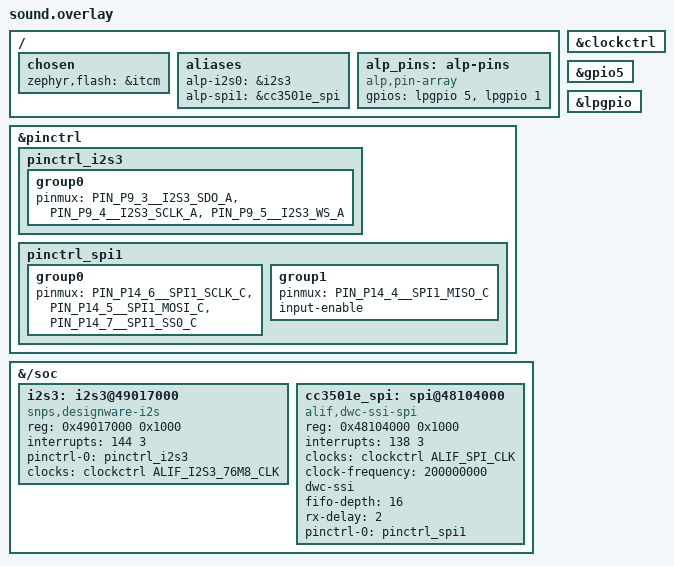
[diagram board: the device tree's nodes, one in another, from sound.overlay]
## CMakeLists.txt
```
# sound/ -- Trace Runner game sound: src/audio's synth on I2S3 -> both
# TAS2563 amps. docs/2026-09-23-sound.md has the build/bench recipes.
#
#   TR_SND_MODE=GAME  (default) the M55-HP firmware: drains the HE's event
#                     ring (src/ipc/tr_aring.h, SRAM0 0x0237F000) into the synth.
#   TR_SND_MODE=TEST  standalone sound test: music + a scripted SFX run, a
#                     1 kHz reference tone, and a PDM-mic loopback capture to
#                     SRAM0 0x02000000 with an in-band PASS/FAIL.
cmake_minimum_required(VERSION 3.20)

set(TR_SND_MODE GAME CACHE STRING "GAME (HP, reads the HE ring) or TEST (standalone loopback test)")
set_property(CACHE TR_SND_MODE PROPERTY STRINGS GAME TEST)
if(NOT TR_SND_MODE MATCHES "^(GAME|TEST)$")
	message(FATAL_ERROR "TR_SND_MODE must be GAME or TEST, got '${TR_SND_MODE}'")
endif()

# Enabling i2s3 drives P9_3/4/5. On an EVK 2626-R2 carrier whose U46 is the
# stock 74LVC157 that contends with U46's outputs (no Hi-Z) the moment the
# pins are muxed -- only a carrier reworked to a 3257-type bus switch (VCC on
# +3V3, E1M-AEN803 serial 2026W36-0002's carrier) may run this image.
option(TR_SND_REWORKED_U46 "Carrier's U46 I2S mux is a reworked 3257-type switch on +3V3" OFF)
if(NOT TR_SND_REWORKED_U46)
	message(FATAL_ERROR "sound/ drives I2S3 through U46: build only for a carrier with the "
		"reworked U46 (-DTR_SND_REWORKED_U46=ON). Stock 74LVC157 carriers contend on P9_3/4/5.")
endif()

list(APPEND DTC_OVERLAY_FILE ${CMAKE_CURRENT_LIST_DIR}/sound.overlay)
# TEST only: OFF = play-only (no PDM node, no DMIC driver, no capture) -- the
# quickest bench check that I2S3 streams, and a split if PDM + I2S3 together
# ever misbehave.
option(TR_SND_MIC "TEST image also captures the PDM mics (loopback verdict)" ON)
if(TR_SND_MODE STREQUAL "TEST")
	if(TR_SND_MIC)
		list(APPEND DTC_OVERLAY_FILE ${CMAKE_CURRENT_LIST_DIR}/pdm.overlay)
		list(APPEND EXTRA_CONF_FILE ${CMAKE_CURRENT_LIST_DIR}/mic.conf)
	endif()
	list(APPEND EXTRA_CONF_FILE ${CMAKE_CURRENT_LIST_DIR}/test.conf)
endif()

find_package(Zephyr REQUIRED HINTS $ENV{ZEPHYR_BASE})
project(trace_runner_sound LANGUAGES C)

# I2S3 and the PDM run off the CGU's 76.8 MHz audio source, which only
# alp-sdk's clockctrl patch (zephyr/patches/zephyr/0001-clock_control_alif-
# master-source-expmst-i2s-setrate.patch) turns on. Unpatched, i2s_dw
# tolerates the missing set_rate silently: the build is clean, the first
# write queues, and nothing ever clocks out (bench, 2026-09-23). Refuse.
file(READ ${ZEPHYR_BASE}/drivers/clock_control/clock_control_alif.c _tr_clkctl)
string(FIND "${_tr_clkctl}" "ALIF_EXPMST0_CTRL_REG_OFF" _tr_patched)
if(_tr_patched EQUAL -1)
	message(FATAL_ERROR "${ZEPHYR_BASE}/drivers/clock_control/clock_control_alif.c lacks alp-sdk's "
		"clockctrl patch (no 76.8 MHz audio clock for I2S3/PDM). Build against a patched tree, "
		"e.g. ZEPHYR_BASE=$ZEPHYR_BASE (docs/2026-09-23-sound.md).")
endif()

target_sources(app PRIVATE
	src/main.c
	src/cc3501e_bridge.c
	src/cc3501e_gpio_routes.c
	../src/audio/tr_audio.c
	../src/audio/tr_amp_ready.c
	../src/ipc/tr_aring.c
)
target_include_directories(app PRIVATE ../src)
# Synth build (bench A/B): TR_SND_V2=OFF renders the first synth version;
# TR_SND_RATE=48000 needs V2 (16 kHz and 48 kHz divide 76.8 MHz exactly).
option(TR_SND_V2 "Band-limited synth + soft limiter + level trims (TR_AUDIO_V2)" ON)
option(TR_SND_V3 "Small-speaker voicing: 4th-order 450 Hz master high-pass + everything voiced from ~500 Hz (TR_AUDIO_V3, needs V2)" ON)
set(TR_SND_RATE 16000 CACHE STRING "Synth and I2S3 rate: 16000 or 48000")
set(TR_SND_VOLUME "" CACHE STRING "Digital volume 0..255 (empty = 255, unity)")
set(TR_SND_AMP_LEVEL "" CACHE STRING "TAS2563 amp analog level code, int or hex 0x01..0x10 (empty = 0x10, 16.0 dBV)")
# Extra TAS2563 register writes for bench A/B, e.g. amp_regs_dvc_minus6db.h
# (DVC -6 dB). Default NONE = the amps' POR DVC 0 dB: round 3 showed no amp
# fault latch in any window with or without it, and it cost 6 dB at the mic.
set(TR_SND_AMP_REGS_FILE NONE CACHE STRING
	"Header defining TR_SND_AMP_REGS (extra TAS2563 writes), or NONE")
target_compile_definitions(app PRIVATE TR_AUDIO_V2=$<BOOL:${TR_SND_V2}> TR_AUDIO_RATE=${TR_SND_RATE}u
	TR_AUDIO_V3=$<AND:$<BOOL:${TR_SND_V2}>,$<BOOL:${TR_SND_V3}>>)
if(TR_SND_VOLUME)
	target_compile_definitions(app PRIVATE TR_SND_VOLUME=${TR_SND_VOLUME}u)
endif()
if(TR_SND_AMP_LEVEL)
	target_compile_definitions(app PRIVATE TR_SND_AMP_LEVEL=${TR_SND_AMP_LEVEL}u)
endif()
if(TR_SND_AMP_REGS_FILE AND NOT TR_SND_AMP_REGS_FILE STREQUAL "NONE")
	target_compile_definitions(app PRIVATE TR_SND_AMP_REGS_FILE="${TR_SND_AMP_REGS_FILE}")
endif()
target_compile_definitions(app PRIVATE TR_SND_TEST=$<IF:$<STREQUAL:${TR_SND_MODE},TEST>,1,0>
	TR_SND_MIC=$<IF:$<AND:$<STREQUAL:${TR_SND_MODE},TEST>,$<BOOL:${TR_SND_MIC}>>,1,0>)
# Same bits as the host tests (the synth is integer-only, but keep the rule).
target_compile_options(app PRIVATE -ffp-contract=off)
```

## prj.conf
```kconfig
# Trace Runner sound firmware (sound/): I2S3 -> both TAS2563 amps, fed by
# src/audio/tr_audio.c. Kconfig set taken from the bench-proven
# aen-i2s-tas2563-probe (2026W36-0002, 2026-09-15) and alp-sdk aen-evk-demo.
CONFIG_ALP_SDK=y

# CC3501E bridge: the I2S0 mux /E + S are CC3501E GPIOs (E1M IO8/IO13).
CONFIG_SPI=y
CONFIG_GPIO=y
CONFIG_ALP_SDK_CHIP_CC3501E=y
CONFIG_ALP_SDK_GPIO_CC3501E_PROXY=y
# IO8 is revision-dependent: the proxy opens it only once the identity
# EEPROM (carrier bus 0 @ 0x50) confirms this hw_rev.
CONFIG_ALP_SDK_CHIP_EEPROM_24C128=y
CONFIG_ALP_SDK_HW_INFO_EEPROM_I2C_BUS_ID=0
CONFIG_ALP_SDK_HW_INFO_EEPROM_I2C_BITRATE_HZ=100000
CONFIG_ALP_SDK_SOM_HW_REV="2626-r2"

# I2S3 TX (<alp/audio.h> audio_out) + TAS2563 x2 over I2C.
CONFIG_I2S=y
CONFIG_AUDIO=y
CONFIG_ALP_SDK_CHIP_TAS2563=y
CONFIG_I2C=y
CONFIG_PINCTRL=y
CONFIG_HEAP_MEM_POOL_SIZE=16384
CONFIG_MAIN_STACK_SIZE=8192

# D-cache maintenance hangs on this silicon, and the event ring in SRAM0 is
# shared with the other M55 -- off (as every AEN bench app and the game).
CONFIG_DCACHE=n
CONFIG_FPU=y
CONFIG_SPEED_OPTIMIZATIONS=y

# RAM console only ('ram_console_buf' over SWD); the HE game owns the UART.
CONFIG_CONSOLE=y
CONFIG_RAM_CONSOLE=y
CONFIG_RAM_CONSOLE_BUFFER_SIZE=8192
CONFIG_UART_CONSOLE=n
CONFIG_PRINTK=y
CONFIG_LOG=n
```

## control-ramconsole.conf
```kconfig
# Extra conf for the 2026W36-0002 CONTROL images (alp-sdk aen-i2s-amp-alif and the
# aen-i2s-tas2563-probe): route printk to 'ram_console_buf', which the Flow C
# helper in alp-sdk scripts/bench/aen reads back (it requires the symbol).
CONFIG_RAM_CONSOLE=y
CONFIG_RAM_CONSOLE_BUFFER_SIZE=16384
CONFIG_UART_CONSOLE=n
```

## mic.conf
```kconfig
# TR_SND_MIC=ON: the PDM mic driver for the loopback capture (pdm.overlay).
CONFIG_AUDIO_DMIC=y
```

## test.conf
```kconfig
# TR_SND_MODE=TEST: float printf for the analysis lines. The DMIC driver
# comes from mic.conf (TR_SND_MIC=ON only).
CONFIG_CBPRINTF_FP_SUPPORT=y
```

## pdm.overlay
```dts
/*
 * Copyright (c) 2026 Alp Lab AB
 * SPDX-License-Identifier: Apache-2.0
 *
 * PDM mics U19/U20 (TR_SND_MODE=TEST only: the loopback listener). From the
 * bench-proven aen-i2s-tas2563-probe overlay: C0 = P6_1, D0 = P6_0, 48 kHz
 * (the MP34DT05 needs a 1.2-3.25 MHz PDM clock; 8/16 kHz modes are below it).
 */
&pinctrl {
	pinctrl_pdm0: pinctrl_pdm0 {
		group0 {
			pinmux = <PIN_P6_1__PDM_C0_C>;
		};
		group1 {
			pinmux = <PIN_P6_0__PDM_D0_C>;
			input-enable;
		};
	};
};

&{/soc} {
	pdm: pdm@4902d000 {
		compatible = "alif,alif-pdm";
		reg = <0x4902d000 0x1000>;
		interrupts = <145 3>, <146 3>, <147 3>;
		interrupt-names = "warning_intr", "error_intr", "audio_det_intr";
		pinctrl-0 = <&pinctrl_pdm0>;
		pinctrl-names = "default";
		clocks = <&clockctrl ALIF_PDM_76M8_CLK>;
		fifo_watermark = <5>;
		bypass_iir_filter = <1>;
		clk-frequency-min = <1200000>;
		clk-frequency-max = <3250000>;
		status = "okay";
	};
};

/ {
	aliases {
		alp-pdm0 = &pdm;
	};
};
```

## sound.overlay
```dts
/*
 * Copyright (c) 2026 Alp Lab AB
 * SPDX-License-Identifier: Apache-2.0
 *
 * Trace Runner sound (sound/): shared by the M55-HE and M55-HP targets --
 * the two AEN803 board files differ only in TCM bases (see
 * docs/2026-09-23-sound.md). Transcribed from the bench-proven
 * aen-i2s-tas2563-probe overlay (2026W36-0002 audible playback 2026-09-15) and
 * alp-sdk examples/aen/aen-evk-demo (AEN803): i2s3 on P9_3/4/5, gpio5 for
 * the amps' SD_N (P5_2) / IRQZ (P5_0), and the CC3501E bridge (SPI1 + the
 * LP-GPIO WIFI_EN/nRESET) that drives the I2S0 mux.
 *
 * i2s3 is ENABLED here. On a carrier whose U46 is the stock 74LVC157 that
 * alone contends with U46's outputs on P9_3/4/5 (alp-sdk
 * examples/aen/aen-i2s-amp-alif README, SAFETY). CMakeLists.txt refuses to
 * build without -DTR_SND_REWORKED_U46=ON for that reason.
 */
#include <zephyr/dt-bindings/pinctrl/alif-ensemble-pinctrl.h>
#include <zephyr/dt-bindings/clock/alif-ensemble-clocks-ext.h>
#include <zephyr/dt-bindings/gpio/gpio.h>

/ {
	chosen {
		zephyr,flash = &itcm; /* RAM-run / SE-load into this core's ITCM */
		/delete-property/ zephyr,code-partition;
	};
	aliases {
		alp-i2s0 = &i2s3;
		alp-spi1 = &cc3501e_spi; /* bus_id 1 in alp_spi_open() */
	};
	/* SoM-internal CC3501E control nets, in cc3501e_bridge.h's
	 * CC3501E_BRIDGE_PIN_* order. Exactly ONE alp,pin-array in the tree. */
	alp_pins: alp-pins {
		compatible = "alp,pin-array";
		gpios = <&lpgpio 5 GPIO_ACTIVE_HIGH>, /* [0] WIFI_EN     (P15_5)      */
			<&lpgpio 1 GPIO_ACTIVE_HIGH>; /* [1] E_WIFI.NRST (P15_1_FLEX) */
	};
};

&pinctrl {
	pinctrl_i2s3: pinctrl_i2s3 {
		group0 {
			pinmux = <PIN_P9_3__I2S3_SDO_A>, <PIN_P9_4__I2S3_SCLK_A>,
				 <PIN_P9_5__I2S3_WS_A>;
		};
	};
	/* SPI1 on P14_6 SCK / P14_5 MOSI / P14_4 MISO + hardware SS0 on P14_7
	 * (the dwc-ssi's own select frames each bridge phase -- no cs-gpios). */
	pinctrl_spi1: pinctrl_spi1 {
		group0 {
			pinmux = <PIN_P14_6__SPI1_SCLK_C>, <PIN_P14_5__SPI1_MOSI_C>,
				 <PIN_P14_7__SPI1_SS0_C>;
		};
		group1 {
			pinmux = <PIN_P14_4__SPI1_MISO_C>;
			input-enable;
		};
	};
};

&{/soc} {
	i2s3: i2s3@49017000 {
		compatible = "snps,designware-i2s";
		reg = <0x49017000 0x1000>;
		interrupts = <144 3>;
		pinctrl-0 = <&pinctrl_i2s3>;
		pinctrl-names = "default";
		clocks = <&clockctrl ALIF_I2S3_76M8_CLK>;
		status = "okay";
	};
	cc3501e_spi: spi@48104000 {
		compatible = "alif,dwc-ssi-spi";
		#address-cells = <1>;
		#size-cells = <0>;
		reg = <0x48104000 0x1000>;
		interrupts = <138 3>;
		clocks = <&clockctrl ALIF_SPI_CLK>;
		clock-frequency = <200000000>;
		dwc-ssi;
		fifo-depth = <16>;
		rx-delay = <2>;
		pinctrl-0 = <&pinctrl_spi1>;
		pinctrl-names = "default";
		status = "okay";
	};
};

&clockctrl {
	status = "okay";
};

&gpio5 {
	status = "okay";
};

&lpgpio {
	status = "okay";
};
```

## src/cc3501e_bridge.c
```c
/*
 * SPDX-License-Identifier: Apache-2.0
 * Copyright 2026 Alp Lab AB
 *
 * E1M-AEN SoM CC3501E bridge bring-up helper -- see cc3501e_bridge.h.
 * Copied from alp-sdk examples/aen/aen-evk-demo/src/cc3501e_bridge.c; the
 * one change: the LP-pad output enable below also runs on the M55-HP
 * (sound/ runs there in the game), not only on the HE.  The warm-aware final
 * reset (no WIFI_EN cycle on a running CC3501E, issue #2797) matches the
 * canonical copy.
 */

#include "cc3501e_bridge.h"

#include <stdio.h>

#if defined(TR_SND_EMBED) && TR_SND_EMBED
/* Combined HP image (sound/src/main.c): the proxy attach below reads the identity EEPROM @0x50
 * on I2C2, which the HE may own -- lease the bus for it (Dekker entry, src/ipc/tr_bus2.h) and
 * GIVE IT BACK right after, before the long, bus-free CC3501E reset: this core's I2C2 IRQ is off
 * and the HE owns the bus again for that whole stretch. A take-back seen at the entry aborts the
 * bring-up (main.c reads its s_aborted); a retry reuses the control-pin and SPI handles opened
 * here. */
#include <stdbool.h>
bool tr_snd_bus_enter(void);
void tr_snd_bus_release(void);
#define BRIDGE_EMBED 1
static alp_gpio_t *s_wifi_en, *s_nrst;
static alp_spi_t  *s_spi;
#else
#define BRIDGE_EMBED 0
#endif

#if defined(CONFIG_SOC_AE822FA0E5597LS0_RTSS_HE) || defined(CONFIG_SOC_AE822FA0E5597LS0_RTSS_HP)
#include <zephyr/arch/cpu.h>
#include <zephyr/devicetree.h>
#include <zephyr/sys/sys_io.h>
/*
 * AEN LP-pad mux (Alif Ensemble E8, M55-HE).  WIFI_EN (P15_5) and nRESET (P15_1)
 * are on the Alif LP-GPIO island, bound by the generic snps,designware-gpio driver
 * which does NOT apply Alif pinctrl -- so the LP pads stay un-muxed and their output
 * drivers OFF (confirmed on silicon: WIFI_EN never powers the CC3501E until these
 * regs are set).  0x23 = the Alif GPIO-output pad config (driver + read-enable +
 * drive strength).  TODO: drop this raw poke once the Alif GPIO backend muxes the LP
 * island via pinctrl.
 */
#define ALIF_LPGPIO_PADCTRL_BASE 0x42007000u
#define ALIF_PAD_GPIO_OUTPUT     0x23u
static void aen_lp_pads_enable_output(void)
{
	sys_write32(ALIF_PAD_GPIO_OUTPUT, ALIF_LPGPIO_PADCTRL_BASE + 5u * 4u); /* P15_5 WIFI_EN */
	sys_write32(ALIF_PAD_GPIO_OUTPUT, ALIF_LPGPIO_PADCTRL_BASE + 1u * 4u); /* P15_1 nRESET  */
}

/* Latch an LP-GPIO pin HIGH in the port's data register while the pad is still an
 * INPUT.  Switching the direction afterwards then drives the already-high level; the
 * other order (direction first, value second -- what gpio_dw's configure does even
 * with an init flag) drives whatever DR holds, and after an LP-GPIO reset that is 0:
 * a glitch on WIFI_EN (P15_5, bit 5) drops the supply of a running chip, one on
 * nRESET (P15_1, bit 1) asserts its reset.  DR is written directly (read-modify-write, the
 * same access gpio_dw's port_set_bits_raw makes) so this template stays on the
 * portable <alp/...> headers: SWPORTA_DR is offset 0x00 of the DesignWare GPIO block
 * (zephyr drivers/gpio/gpio_dw_registers.h), the block base is the `lpgpio` node's
 * reg, and the LP-GPIO clock is already on because alp_gpio_open() opened the pin. */
#define DW_GPIO_SWPORTA_DR 0x00u
static void aen_lp_gpio_latch_high(unsigned int bit)
{
	const mem_addr_t dr = DT_REG_ADDR(DT_NODELABEL(lpgpio)) + DW_GPIO_SWPORTA_DR;

	sys_write32(sys_read32(dr) | (1u << bit), dr);
}

#else
static inline void aen_lp_pads_enable_output(void)
{
}

static inline void aen_lp_gpio_latch_high(unsigned int bit)
{
	(void)bit;
}
#endif

alp_status_t cc3501e_bridge_bringup(cc3501e_t *fw)
{
	if (fw == NULL) {
		return ALP_ERR_INVAL;
	}

	/* 1. Control pins: WIFI_EN (supply gate) + nRESET.  These are Alif LP-GPIO
	 *    pads, not E1M edge pads -- the SoM owns them. */
#if BRIDGE_EMBED
	alp_gpio_t *wifi_en = s_wifi_en != NULL ? s_wifi_en : alp_gpio_open(CC3501E_BRIDGE_PIN_WIFI_EN);
	alp_gpio_t *nrst    = s_nrst != NULL ? s_nrst : alp_gpio_open(CC3501E_BRIDGE_PIN_NRST);
	s_wifi_en           = wifi_en;
	s_nrst              = nrst;
#else
	alp_gpio_t *wifi_en = alp_gpio_open(CC3501E_BRIDGE_PIN_WIFI_EN);
	alp_gpio_t *nrst    = alp_gpio_open(CC3501E_BRIDGE_PIN_NRST);
#endif
	if (wifi_en == NULL || nrst == NULL) {
		if (wifi_en != NULL) {
			alp_gpio_close(wifi_en);
		}
		if (nrst != NULL) {
			alp_gpio_close(nrst);
		}
		return ALP_ERR_NOT_PRESENT_ON_THIS_SOC;
	}
	aen_lp_pads_enable_output();
	/* Sample the supply gate BEFORE touching its direction.  High is only a HINT
	 * that the chip may be powered -- an external pull-up on WIFI_EN would make every
	 * power-on read high (whether the module has one is an OPEN QUESTION; the
	 * netlist has not been checked), so the decision below also needs a PING. */
	bool wifi_was_high = false;
	/* A failed read leaves the level unknown: never take the supply-cycling cold path
	 * on that alone -- go through the PING path below, which still ends in
	 * cc3501e_reset() if the chip turns out to be silent. */
	const bool wifi_unknown = alp_gpio_read(wifi_en, &wifi_was_high) != ALP_OK;
	if (wifi_was_high || wifi_unknown) {
		/* Latch the level in DR first so the direction change cannot glitch it low.  An
		 * unknown level is latched high too: DR bit 5 = 0 would otherwise drop the supply
		 * of a chip that is already running the moment the pin becomes an output. */
		aen_lp_gpio_latch_high(5u); /* P15_5 WIFI_EN */
	}
	/* Same for nRESET: a running chip has it released (high).  Without the latch the
	 * direction change below drives DR bit 1 = 0 and holds the chip in reset, so the
	 * warm PING always fails and the bring-up falls through to a WIFI_EN supply cycle. */
	bool nrst_was_high = false;
	if (alp_gpio_read(nrst, &nrst_was_high) == ALP_OK && nrst_was_high) {
		aen_lp_gpio_latch_high(1u); /* P15_1 nRESET */
	}
	(void)alp_gpio_configure(wifi_en, ALP_GPIO_OUTPUT, ALP_GPIO_PULL_NONE);
	(void)alp_gpio_configure(nrst, ALP_GPIO_OUTPUT, ALP_GPIO_PULL_NONE);

	/* 2. Inter-chip SPI (Alif = master).  CS is the dwc-ssi hardware SS0
	 *    muxed on P14_7; the app passes ALP_SPI_NO_CS so no software GPIO CS
	 *    is installed and the SPI controller drives SS0 per transfer.  Mode 0
	 *    matches the CC3501E vendor image frameFormat. */
#if BRIDGE_EMBED
	alp_spi_t *spi = s_spi != NULL ? s_spi : alp_spi_open(&(alp_spi_config_t) {
#else
	alp_spi_t *spi = alp_spi_open(&(alp_spi_config_t){
#endif
		.bus_id = CC3501E_BRIDGE_SPI_BUS_ID, .freq_hz = CC3501E_BRIDGE_SPI_FREQ_HZ,
		.mode = ALP_SPI_MODE_0, .bits_per_word = 8u, .cs_pin_id = ALP_SPI_NO_CS,
	});
#if BRIDGE_EMBED
	s_spi = spi;
#endif
	if (spi == NULL) {
		alp_gpio_close(wifi_en);
		alp_gpio_close(nrst);
		return ALP_ERR_NOT_PRESENT_ON_THIS_SOC;
	}

#if CC3501E_BRIDGE_RX_SAMPLE_DLY > 0
	/* Raise the SCLK past 1 MHz: the DW SSI RX_SAMPLE_DLY register (0xf0) delays
	 * the MISO capture point by N ssi_clk cycles to cover the on-SoM trace + crossed
	 * data round-trip.  Zephyr spi_dw never writes it (leaves 0), so without this
	 * >1 MHz mis-samples MISO (cold reqhdr_rx=0xFFFFFFFF).  Written with SSI disabled
	 * (SSIENR=0); persists across the driver's per-transfer configure.  Value is
	 * silicon-tuned -- sweep CC3501E_BRIDGE_RX_SAMPLE_DLY at the target SCLK.
	 *
	 * SWEEP TRAP -- read before setting the constant to 0: the `#if > 0` above
	 * compiles this block out, so 0 does not mean "no delay", it means the SPI
	 * node's `rx-delay` devicetree value is left in place.  aen-cc3501e-bringup
	 * and aen-evk-demo declare rx-delay = <2>, so a naive N=0 sweep point on
	 * those two silently measures 2.  Read 0x481040F0 back to see what the link
	 * is actually running at. */
	{
		volatile uint32_t *ssienr =
		    (volatile uint32_t *)(uintptr_t)(CC3501E_BRIDGE_SPI1_BASE + 0x08u);
		volatile uint32_t *rsd = (volatile uint32_t *)(uintptr_t)(CC3501E_BRIDGE_SPI1_BASE + 0xf0u);
		uint32_t           en  = *ssienr;
		*ssienr                = 0u;
		*rsd                   = (uint32_t)CC3501E_BRIDGE_RX_SAMPLE_DLY;
		*ssienr                = en;
	}
#endif

	/* 3. Bind the bus + control pins; attach the GPIO proxy (proxied E1M IOs then
	 *    route over the bridge); run the power + reset sequence (TI SWRU626 + the
	 *    Puya cold-boot hard-reset workaround).  Leaves WIFI_EN HIGH. */
	(void)cc3501e_init(fw, spi);
	fw->enable_pin = wifi_en;
	fw->reset_pin  = nrst;
	/* READY (CC35 GPIO17) is NOT wired here by default on this R2 module --
	 * see chips/cc3501e/cc3501e_core.c's cc3501e_reply_gate() comment for the
	 * pin-routing fact, the bench evidence, and how a board that genuinely
	 * wires it can opt back in via fw->ready_pin. */
#ifdef CONFIG_ALP_SDK_GPIO_CC3501E_PROXY
#if BRIDGE_EMBED
	if (!tr_snd_bus_enter()) {
		return ALP_ERR_BUSY; /* the HE took I2C2 back: no EEPROM read */
	}
#endif
	(void)alp_gpio_cc3501e_attach(fw); /* reads the identity EEPROM @0x50 on I2C2 */
#if BRIDGE_EMBED
	tr_snd_bus_release();
#endif
#endif
#ifdef CONFIG_ALP_SDK_WIFI_CC3501E
	(void)alp_wifi_cc3501e_attach(fw);
#endif
#ifdef CONFIG_ALP_SDK_BLE_CC3501E
	(void)alp_ble_cc3501e_attach(fw);
#endif
	/* One line naming the path taken, so a log shows whether the supply was cycled. */
	if (!wifi_was_high && !wifi_unknown) {
		printf("[cc3501e_bridge] WIFI_EN low: cold power-up (cc3501e_reset)\n");
		return cc3501e_reset(fw); /* supply low: the full cold-boot sequence */
	}
	/* WIFI_EN reads high.  Warm = the chip ANSWERS a PING; a pull-up alone proves
	 * nothing.  Warm: nRESET only, never a WIFI_EN toggle. */
	if (cc3501e_ping(fw) == ALP_OK) {
		printf("[cc3501e_bridge] WIFI_EN high, PING ok: warm, nRESET only\n");
		return cc3501e_hard_reset(fw);
	}
	/* High but silent: powered-and-hung, or unpowered behind a pull-up.  Try the
	 * nRESET-only reset first (safe for a powered chip); only if the chip still does
	 * not answer is the supply cycled -- the last resort, taken from a chip that is
	 * already unresponsive. */
	if (cc3501e_hard_reset(fw) == ALP_OK && cc3501e_ping(fw) == ALP_OK) {
		printf("[cc3501e_bridge] WIFI_EN high, silent: recovered by nRESET only\n");
		return ALP_OK;
	}
	printf("[cc3501e_bridge] WIFI_EN high, silent after nRESET: supply cycle (cc3501e_reset)\n");
	return cc3501e_reset(fw);
}
```

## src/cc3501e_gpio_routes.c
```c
/*
 * SPDX-License-Identifier: Apache-2.0
 * Copyright 2026 Alp Lab AB
 *
 * Strong override of the SDK's WEAK (empty) cc3501e_gpio_routes[]: the two
 * CC3501E-proxied pins this app drives, the I2S0 mux in front of the TAS2563
 * amps. Same table as the bench-proven aen-i2s-tas2563-probe; hw_rev
 * 2626-r2 routes (IO8 -> GPIO_30 holds only on r2 -- the SDK's per-pin guard
 * refuses IO8 unless the identity EEPROM confirms CONFIG_ALP_SDK_SOM_HW_REV).
 */
#include <stddef.h>

#include <alp/chips/cc3501e.h>
#include <alp/e1m_pinout.h>

const cc3501e_gpio_route_t cc3501e_gpio_routes[] = {
	{ ALP_E1M_GPIO_IO13,
	  13u }, /* I2S0 mux S (I2S_SELECT): 0 = TAS2563 amps. NEVER drive 1 on a reworked carrier. */
	{ ALP_E1M_GPIO_IO8, 30u }, /* I2S0 mux /E (I2S_EN), active low. */
};
const size_t cc3501e_gpio_route_count =
    sizeof(cc3501e_gpio_routes) / sizeof(cc3501e_gpio_routes[0]);
```

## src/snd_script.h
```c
/* sound/src/snd_script.h -- the TEST image's per-effect loopback script,
 * shared with tools/audio_preview.c (--script) so the PC renders the exact
 * samples the image streams: same windows, same seeds, same synth build.
 *
 * Every window restarts the synth (tr_audio_init) so each clip is isolated
 * and deterministic; the stream itself never stops. Window lengths are in
 * 16 ms blocks (SND_BLOCK_MS), the I2S and mic block period at any rate.
 */
#ifndef SND_SCRIPT_H
#define SND_SCRIPT_H

#include <stdint.h>
#include <string.h>

#include "audio/tr_audio.h"
#include "ipc/tr_mbox.h" /* TR_CRASH_KIND_* */

#define SND_BLOCK_MS 16u
#define SND_FRAMES   (TR_AUDIO_RATE * SND_BLOCK_MS / 1000u) /* 256 at 16 kHz, 768 at 48 kHz */
#define SND_SEED     0x7E57u

enum { SND_W_SILENCE, SND_W_TONE, SND_W_MUSIC, SND_W_SFX };

typedef struct {
	uint8_t     type, kind, param;
	uint16_t    hz, amp; /* SND_W_TONE: frequency, peak amplitude (S16) */
	uint16_t    blocks;
	const char *name;
} snd_win_t;

/* 1 kHz at -12 and -3 dBFS, and 200/300/500 Hz at -6 dBFS: harmonic
 * distortion of the chain vs level, and where the speakers' usable low end
 * starts (200 Hz came back THD +33.9 dB on 2026-09-23). Music from bar 9 (lead + drums). Each effect alone. */
static const snd_win_t snd_windows[] = {
	{ SND_W_SILENCE, 0, 0, 0, 0, 31, "silence" },
	{ SND_W_TONE, 0, 0, 1000, 8231, 62, "tone1k_-12dBFS" },
	{ SND_W_TONE, 0, 0, 1000, 23197, 62, "tone1k_-3dBFS" },
	{ SND_W_TONE, 0, 0, 200, 16423, 62, "tone200_-6dBFS" },
	{ SND_W_TONE, 0, 0, 300, 16423, 62, "tone300_-6dBFS" },
	{ SND_W_TONE, 0, 0, 400, 16423, 62, "tone400_-6dBFS" },
	{ SND_W_TONE, 0, 0, 500, 16423, 62, "tone500_-6dBFS" },
	{ SND_W_MUSIC, TR_AEV_MUSIC, TR_MUSIC_PLAY, 0, 0, 625, "music" },
	{ SND_W_SFX, TR_AEV_FOOTSTEP, 0, 0, 0, 38, "footstep" },
	{ SND_W_SFX, TR_AEV_PICKUP, 0, 0, 0, 50, "pickup" },
	{ SND_W_SFX, TR_AEV_PICKUP, 6, 0, 0, 50, "pickup_combo6" },
	{ SND_W_SFX, TR_AEV_JUMP, 0, 0, 0, 50, "jump" },
	{ SND_W_SFX, TR_AEV_DUCK, 0, 0, 0, 50, "duck" },
	{ SND_W_SFX, TR_AEV_CRASH, TR_CRASH_KIND_LOW, 0, 0, 75, "crash" },
	{ SND_W_SFX, TR_AEV_CRASH, TR_CRASH_KIND_WIRE, 0, 0, 75, "crash_wire" },
	{ SND_W_SFX, TR_AEV_WIRE, 255, 0, 0, 62, "wire" },
	{ SND_W_SFX, TR_AEV_ATTRACT, 0, 0, 0, 100, "attract_jingle" },
	{ SND_W_SFX, TR_AEV_GAME_OVER, 0, 0, 0, 150, "game_over" },
};
#define SND_WINDOWS (sizeof(snd_windows) / sizeof(snd_windows[0]))

static const int16_t snd_sin256[257] = {
	0,      804,    1608,   2410,   3212,   4011,   4808,   5602,   6393,   7179,   7962,   8739,
	9512,   10278,  11039,  11793,  12539,  13279,  14010,  14732,  15446,  16151,  16846,  17530,
	18204,  18868,  19519,  20159,  20787,  21403,  22005,  22594,  23170,  23731,  24279,  24811,
	25329,  25832,  26319,  26790,  27245,  27683,  28105,  28510,  28898,  29268,  29621,  29956,
	30273,  30571,  30852,  31113,  31356,  31580,  31785,  31971,  32137,  32285,  32412,  32521,
	32609,  32678,  32728,  32757,  32767,  32757,  32728,  32678,  32609,  32521,  32412,  32285,
	32137,  31971,  31785,  31580,  31356,  31113,  30852,  30571,  30273,  29956,  29621,  29268,
	28898,  28510,  28105,  27683,  27245,  26790,  26319,  25832,  25329,  24811,  24279,  23731,
	23170,  22594,  22005,  21403,  20787,  20159,  19519,  18868,  18204,  17530,  16846,  16151,
	15446,  14732,  14010,  13279,  12539,  11793,  11039,  10278,  9512,   8739,   7962,   7179,
	6393,   5602,   4808,   4011,   3212,   2410,   1608,   804,    0,      -804,   -1608,  -2410,
	-3212,  -4011,  -4808,  -5602,  -6393,  -7179,  -7962,  -8739,  -9512,  -10278, -11039, -11793,
	-12539, -13279, -14010, -14732, -15446, -16151, -16846, -17530, -18204, -18868, -19519, -20159,
	-20787, -21403, -22005, -22594, -23170, -23731, -24279, -24811, -25329, -25832, -26319, -26790,
	-27245, -27683, -28105, -28510, -28898, -29268, -29621, -29956, -30273, -30571, -30852, -31113,
	-31356, -31580, -31785, -31971, -32137, -32285, -32412, -32521, -32609, -32678, -32728, -32757,
	-32767, -32757, -32728, -32678, -32609, -32521, -32412, -32285, -32137, -31971, -31785, -31580,
	-31356, -31113, -30852, -30571, -30273, -29956, -29621, -29268, -28898, -28510, -28105, -27683,
	-27245, -26790, -26319, -25832, -25329, -24811, -24279, -23731, -23170, -22594, -22005, -21403,
	-20787, -20159, -19519, -18868, -18204, -17530, -16846, -16151, -15446, -14732, -14010, -13279,
	-12539, -11793, -11039, -10278, -9512,  -8739,  -7962,  -7179,  -6393,  -5602,  -4808,  -4011,
	-3212,  -2410,  -1608,  -804,   0

};

/* Index of the first window of `type` (the verdict's silence/tone/music). */
static inline unsigned snd_window_of(uint8_t type)
{
	for (unsigned i = 0; i < SND_WINDOWS; i++) {
		if (snd_windows[i].type == type) return i;
	}
	return 0;
}

/* Block `blk` of window `w` into mono[SND_FRAMES]. *phase: tone phase. */
static inline void
snd_script_block(const snd_win_t *w, unsigned blk, int16_t *mono, uint32_t *phase)
{
	if (blk == 0u) {
		*phase = 0u;
		tr_audio_init(SND_SEED);
		if (w->type == SND_W_MUSIC) {
			tr_audio_event(TR_AEV_MUSIC, TR_MUSIC_PLAY);
			tr_audio_seek(8u * 16u); /* bar 9: lead, kick, snare */
		} else if (w->type == SND_W_SFX) {
			tr_audio_event(w->kind, w->param);
		}
	}
	if (w->type == SND_W_TONE) {
		uint32_t inc = (uint32_t)(((uint64_t)w->hz << 32) / TR_AUDIO_RATE);
		for (unsigned i = 0; i < SND_FRAMES; i++) {
			uint32_t idx = *phase >> 24, fr = (*phase >> 8) & 0xFFFFu;
			int32_t  a = snd_sin256[idx], b = snd_sin256[idx + 1u];
			int32_t  v = a + (int32_t)(((int64_t)(b - a) * fr) >> 16);
			mono[i]    = (int16_t)((v * w->amp) >> 15);
			*phase += inc;
		}
	} else if (w->type == SND_W_SILENCE) {
		memset(mono, 0, SND_FRAMES * sizeof(int16_t));
	} else {
		tr_audio_render(mono, SND_FRAMES);
	}
}

#endif /* SND_SCRIPT_H */
```

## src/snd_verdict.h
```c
/* sound/src/snd_verdict.h -- PASS/FAIL rule of the TEST image's PDM-mic
 * loopback, pure C so the host test (tests/host/test_snd_verdict.c) can feed
 * it the capture that fooled the first version: every sample 0, every I2S
 * write failed, and it still printed PASS because 0 >= 100 * 0.
 * tools/audio_spectro.py applies the same rule to a capture dump.
 *
 * Windows: 0 silence (stream running, zeros), 1 = 1 kHz tone, 2 = music+SFX.
 * rms = AC RMS per mic, bin = normalised 1 kHz Goertzel power (A^2/4 for a
 * sine of amplitude A), both in S16 LSB units.
 */
#ifndef SND_VERDICT_H
#define SND_VERDICT_H

#include <stdint.h>

#define SND_MAX_FAILS   2u    /* write or mic-read failures tolerated per run */
#define SND_LIVE_RMS    0.5f  /* a working PDM mic is never digitally silent */
#define SND_TONE_FLOOR  25.0f /* 1 kHz bin >= amplitude 10 LSB */
#define SND_MUSIC_FLOOR 5.0f  /* music window AC RMS in LSB */

typedef struct {
	float    rms[3][2], bin[3][2];
	uint32_t frames, want_frames;
	uint32_t write_fail, mic_fail;
	uint32_t played_ms, want_ms;
} snd_stats_t;

/* NULL = PASS, else the first reason it failed. */
static inline const char *snd_verdict(const snd_stats_t *s)
{
	if (s->write_fail > SND_MAX_FAILS) return "I2S3 writes failed (bit clock not running?)";
	if (s->mic_fail > SND_MAX_FAILS) return "PDM mic reads failed";
	if (s->frames != s->want_frames) return "capture incomplete";
	if (s->played_ms > s->want_ms + s->want_ms / 10u) return "playback slower than real time";

	unsigned live = 0, tone = 0, music = 0;
	for (unsigned c = 0; c < 2u; c++) {
		if (!(s->rms[0][c] >= SND_LIVE_RMS)) continue; /* dead or all-zero channel proves nothing */
		live++;
		float b0 = s->bin[0][c], b1 = s->bin[1][c], r1 = s->rms[1][c];
		if (b1 >= SND_TONE_FLOOR && b1 >= 100.0f * b0 && 2.0f * b1 >= 0.1f * r1 * r1) tone++;
		if (s->rms[2][c] >= SND_MUSIC_FLOOR && s->rms[2][c] >= 2.0f * s->rms[0][c]) music++;
	}
	if (live == 0u) return "no live mic (silence window digitally zero)";
	if (tone == 0u) return "1 kHz tone not heard";
	if (music == 0u) return "music not heard";
	return 0;
}

#endif /* SND_VERDICT_H */
```
